# STM32WB07 register map
File version: 0.4
CPU: CM0+ r0p0, little endian, MPU, no FPU, 2 interrupt priority bits
Registers are 32-bit, read-write, reset 0x0 unless marked. A register's access mark holds for its fields unless they carry their own. Offsets are from the block's base; [hi:lo] are bit positions; {n}, {i} and the like mark numbered series; 'fields as' and 'values as' point back to an identical list; <NAME> marks a mode.

## PWRC
Base 0x48500000
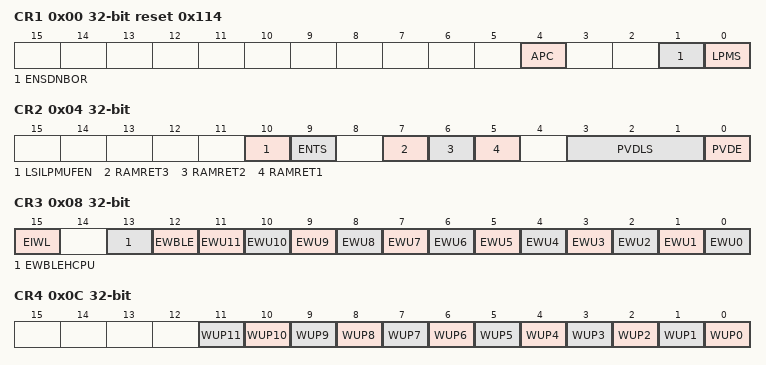
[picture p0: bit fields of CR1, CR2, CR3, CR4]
0x00 CR1 reset 0x114
  [4] APC — APC Apply Pull-up and pull-down configuration from CPU
    1=the I/O pull-up and pull-down configurations defined in the PUCRx and PDCRx registers is applied; 0=the PUCRx and PDCRx are not used to control the I/O pull-up and pull-down configuration of the product I/Os
  [1] ENSDNBOR — Enable BOR reset supervising during SHUTDOWN mode.
  [0] LPMS — LPMS Low Power Mode Selection Selection of the low power mode entered when CPU enters DEEP SLEEP mode and BLE is rdy2sleep.
    0=Deep Stop mode (default); 1=Shutdown mode
0x04 CR2
  [10] LSILPMUFEN — LSI LPMU force enable.
  [9] ENTS — Enable the temperature sensor.
  [7] RAMRET3 — Enables the RAM3 bank retention in DEEPSTOP mode.
    1=Temperature sensor is enabled; 0=Temperature sensor is disabled
  [6] RAMRET2 — Enables the RAM2 bank retention in DEEPSTOP mode.
  [5] RAMRET1 — RAMRET1: RAM1 retention during low power mode
    1=RAM1 bank is powered during low power mode; 0=RAM1 bank is disabled during low power mode (by default)
  [3:1] PVDLS — PVDLS[2:0] Programmable Voltage Detector Level selection then PVDO=1)
    0=2.05 V - Lowest level; 1=2.20 V; 2=2.36 V; 3=2.52 V; 4=2.64 V; 5=2.81 V; 6=2.91 V - Highest level; 7=External input analog voltage (compare internally to VBGP; When external input <VBGP
  [0] PVDE — PVDE Programmable Voltage Detector Enable When this bit is set the Power Voltage Detector is enabled
0x08 CR3
  [15] EIWL — EIWL: Enable wakeup on Internal event (RTC). 0: Wakeup on internal line is disabled (default). 1: Wakeup on internal line is enabled.
  [13] EWBLEHCPU — EWBLEHCPU: Enable wakeup on BLE Host CPU event. 0: Wakeup on BLE Host CPU line is disabled (default). 1: Wakeup on BLE Host CPU line is enabled.
  [12] EWBLE — EWBLE: Enable wakeup on BLE event. 0: Wakeup on BLE line is disabled (default). 1: Wakeup on BLE line is enabled.
  [n] EWU{n} (n=8..11) — EWU{n} Enable WakeUp line {n} (PA{n}) When this bit is set the wakeup line {n} is enabled and a rising or falling edge on wakeup line {n} will trigger a CPU wakeup event depending on CR4.WP{n} bit.
  [n] EWU{n} (n=0..7) — EWU{n} Enable WakeUp line {n} (PB{n}) When this bit is set the wakeup line {n} is enabled and a rising or falling edge on wakeup line {n} will trigger a CPU wakeup event depending on CR4.WP{n} bit.
0x0C CR4
  [all] fields
    0=Detection on high level (rising edge); 1=Detection on low level (falling edge)
  [n] WUP{n} (n=8..11) — WUP{n} Wake-up Line Polarity {n} (PA{n}) This bit defines the polarity used for event detection on external wake-up line {n}
  [n] WUP{n} (n=0..7) — WUP{n} Wake-up Line Polarity {n} (PB{n}) This bit defines the polarity used for event detection on external wake-up line {n}
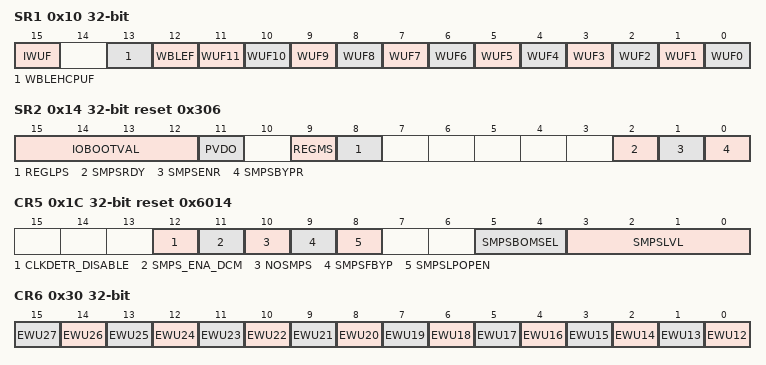
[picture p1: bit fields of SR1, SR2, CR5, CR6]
0x10 SR1
  [15] IWUF ro — IWUF: Internal wakeup flag (RTC). 0: no wakeup from RTC occurred since last clear. 1: a wakeup from RTC occurred since last clear. Note: The user must clear the RTC wakeup flag inside the RTC IP to clear this bit (mirror of the RTC wakeup line on the PWRC block).
  [13] WBLEHCPUF — WBLEHCPUF: BLE Host CPU wakeup flag. 0: no wakeup from BLE Host CPU occurred since last clear. 1: a wakeup from BLE Host CPU occurred since last clear. Cleared by writing 1 in this bit.
  [12] WBLEF — WBLEF: BLE wakeup flag. 0: no wakeup from BLE occurred since last clear. 1: a wakeup from BLE occurred since last clear. Cleared by writing 1 in this bit.
  [n] WUF{n} (n=8..11) — WUF{n} WakeUp Flag {n} (PA{n}) This bit is set when a wakeup is detected on wakeup line {n}. It is cleared by a reset pad or by writing 1 in this bit field. writting this bit, clears the interrupt:
    0=no effect; 1=clear the interrupt
  [n] WUF{n} (n=0..7) — WUF{n} WakeUp Flag {n} (PB{n}) This bit is set when a wakeup is detected on wakeup line {n}. It is cleared by a reset pad or by writing 1 in this bit field. writting this bit, clears the interrupt:
    0=no effect; 1=clear the interrupt
0x14 SR2 ro reset 0x306
  [15:12] IOBOOTVAL — Bit3: PA11 input value on VDD33 latched at POR Bit2: PA10 input value on VDD33 latched at POR Bit1: PA9 input value on VDD33 latched at POR Bit0: PA8 input value on VDD33 latched at POR
  [11] PVDO — PVDO: Power Voltage Detector Output When the Power Voltage Detector is enabled (CR2.PVDE) this bit is set when the system supply (VDDIO) is lower than the selected PVD threshold (CR2.PVDLS)
  [9] REGMS — REGMS: Regulator Main LDO Started This bit provides the information whether main regulator is ready.
    0=Main regulator is not ready; 1=Main regulator is ready
  [8] REGLPS — REGLPS: Regulator Low Power Started This bit provides the information whether low power regulator is ready.
    0=LP regulator is not ready; 1=LP regulator is ready
  [2] SMPSRDY — SMPSRDY: SMPS Ready Status This bit provides the information whether SMPS is ready.
    0=SMPS regulator is not ready; 1=SMPS regulator is ready
  [1] SMPSENR — SMPSENR: SMPS Enable Control Replica This bit mirrors the actual ENABLE_3V3 control signal driven to the SMPS regulator, dependant on the real working state.
  [0] SMPSBYPR — SMPSBYPR: SMPS Force Bypass Control Replica This bit mirrors the actual BYPASS_3V3 control signal driven to the SMPS regulator, dependant on the real working state.
0x1C CR5 reset 0x6014
  [12] CLKDETR_DISABLE — CLKDETR_DISABLE: disable SMPS clock detection The SMPS clock detection enables an automatic SMPS bypass switching in case of unwanted loss of SMPS clock.
    0=SMPS clock detection enabled (default); 1=SMPS clock detection disabled
  [11] SMPS_ENA_DCM — SMPS_ENA_DCM: enable discontinuous conduction mode
    0=disable; 1=enable
  [10] NOSMPS — NOSMPS: No SMPS Mode When this bit is set, the SMPS regulator will be disabled. Note that this configuration should be used only when SMPS_FB pad is directly connected to VBATT or Vext, without L/C BOM.
    0=No effect, SMPS is enabled; 1=SMPS is disabled;
  [9] SMPSFBYP — SMPSFB Force SMPS Regulator in bypass mode When this bit is set, the SMPS regulator will be forced to operate in precharge mode. the actual state of SMPS can be observed thanks to the replica SR2.SMPSBYPR.
    0=no effect (by default); 1=SMPS is disabled and bypassed (ENABLE_3V3=0 and PRECHARGE_3V3=1)
  [8] SMPSLPOPEN — SMPSLPOPEN: In Low Power mode SMPS is in OPEN mode (instead of PRECHARGE mode). When this bit is set, when the chip is in Low power mode the SMPS regulator will be disabled (HZ) Documentation needed.
    0=in Low Power mode, SMPS is in PRECHARGE, output is connected to VDDIO; 1=in Low Power mode, SMPS is disabled, output is floating
  [5:4] SMPSBOMSEL — SMPSBOMSEL: SMPS BOM Selection:
    0=BOM1; 1=BOM2 (default); 2=BOM3; 3=n/a
  [3:0] SMPSLVL — SMPSLVL[3:0] SMPS Output Level Voltage Selection Select the SMPS output voltage with a granularity of 50mV. Default = '0100' (1.4V) Vout = 1.2 + 0.05*SMPSOUT (V)
0x20 PUCRA reset 0xF07
  [15:0] PUA — PUA[x] : Pull Up Pull up activation on port A[i] pad when APC bit of PWRC CR3 is set
    1=Pull-Up activated on port A[i] when APC bit of PWRC CR3 bit is set and PWR_PDCRA[x] is reset; 0=Pull-Up not activated on port A[i]
0x24 PDCRA reset 0x8
  [15:0] PDA — PDA[x]: Pull Down Pull Down activation on port A[i] pad when APC bit of PWRC CR3 is set
    1=Pull-Down activated on Port A[i] when APC bit of PWRC CR3 bit is set; 0=Pull-Down not activated on Port A[i]
0x28 PUCRB reset 0xF0FF
  [15:0] PUB — PUB[x] : Pull Up Pull up activation on port B[i] pad when APC bit of PWRC CR3 is set
    1=Pull-Up activated on port B[i] when APC bit of PWRC CR3 bit is set and PWR_PDCRB[x] is reset; 0=Pull-Up not activated on port B[i]
0x2C PDCRB
  [15:0] PDB — PDB[x]: Pull Down Pull Down activation on port B[i] pad when APC bit of PWRC CR3 is set
    1=Pull-Down activated on Port B[i] when APC bit of PWRC CR3 bit is set; 0=Pull-Down not activated on Port B[i]
0x30 CR6
  [n-12] EWU{n} (n=24..27) — Enable wakeup on PA{n-12} I/O event.
  [n-12] EWU{n} (n=20..23) — Enable wakeup on PB{n-12} I/O event.
  [n-12] EWU{n} (n=16..19) — EWU{n} Enable WakeUp line {n} (PB{n-4}) When this bit is set the wakeup line {n} is enabled and a rising or falling edge on wakeup line {n-12} will trigger a CPU wakeup event depending on CR7.WP{n-12} bit.
  [n-12] EWU{n} (n=12..15) — EWU{n} Enable WakeUp line {n} (PA{n-12}) When this bit is set the wakeup line {n} is enabled and a rising or falling edge on wakeup line {n-12} will trigger a CPU wakeup event depending on CR7.WP{n-12} bit.
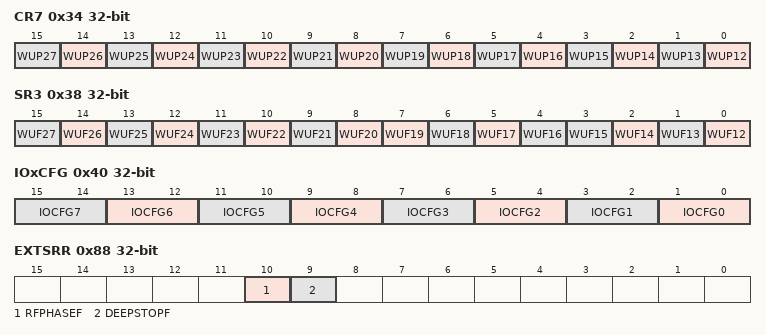
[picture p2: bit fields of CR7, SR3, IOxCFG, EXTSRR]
0x34 CR7
  [n-12] WUP{n} (n=20..27) — Wake-up polarity for PB{n-12} IO event.
  [n-12] WUP{n} (n=16..19) — WUP{n} Wake-up Line Polarity {n} (PB{n-4}) This bit defines the polarity used for event detection on external wake-up line {n}
    values as the fields of CR4
  [n-12] WUP{n} (n=12..15) — WUP{n} Wake-up Line Polarity {n} (PA{n-12}) This bit defines the polarity used for event detection on external wake-up line {n}
    values as the fields of CR4
0x38 SR3
  [n-12] WUF{n} (n=20..27) — PB{n-12} I/O wake-up flag.
  [7] WUF19 — PA7 I/O wake-up flag.
    0=no effect; 1=clear the interrupt
  [6] WUF18 — WUF18 WakeUp Flag 18 PB14 This bit is set when a wakeup is detected on wakeup line 18. It is cleared by a reset pad or by writing 1 in this bit field. writting this bit, clears the interrupt:
    0=no effect; 1=clear the interrupt
  [5] WUF17 — WUF17 WakeUp Flag 17 PB13 This bit is set when a wakeup is detected on wakeup line 17. It is cleared by a reset pad or by writing 1 in this bit field. writting this bit, clears the interrupt:
    0=no effect; 1=clear the interrupt
  [4] WUF16 — WUF16 WakeUp Flag 16 PB12 This bit is set when a wakeup is detected on wakeup line 16. It is cleared by a reset pad or by writing 1 in this bit field. writting this bit, clears the interrupt:
    0=no effect; 1=clear the interrupt
  [n-12] WUF{n} (n=12..15) — WUF{n} WakeUp Flag {n} PA{n-12} This bit is set when a wakeup is detected on wakeup line {n}. It is cleared by a reset pad or by writing 1 in this bit field. writting this bit, clears the interrupt:
    0=no effect; 1=clear the interrupt
0x40 IOxCFG
  [2n+1:2n] IOCFG{n} (n=4..7) — Drive configuration for PA{n}.
  [2n+1:2n] IOCFG{n} (n=0..3) — Drive configuration for PA{n+8}.
0x84 DBGR
  [0] DEEPSTOP2 — DEEPSTOP2: DEEPSTOP2 low power saving emulation enable. 0: normal DEEPSTOP will be applied 1: DEEPSTOP2 (debugger features not lost) will be applied instead of DEEPSTOP.
0x88 EXTSRR
  [10] RFPHASEF — RFPHASEF RFPHASE Flag This bit is set by hardware after a Radio wake-up event (BLE activation); it is cleared either by software, writing '1' in this bit field, or by hardware when Ready2Sleep signal is asserted by the Radio IP.
    0=RF IP does not require attention; 1=RF IP awake and requesting system attention
  [9] DEEPSTOPF — DEEPSTOPF System DeepStop Flag This bit is set by hardware and cleared only by a POR reset or by writing '1' in this bit field
    0=System has not been in DEEPSTOP mode; 1=System has been in DEEPSTOP mode
